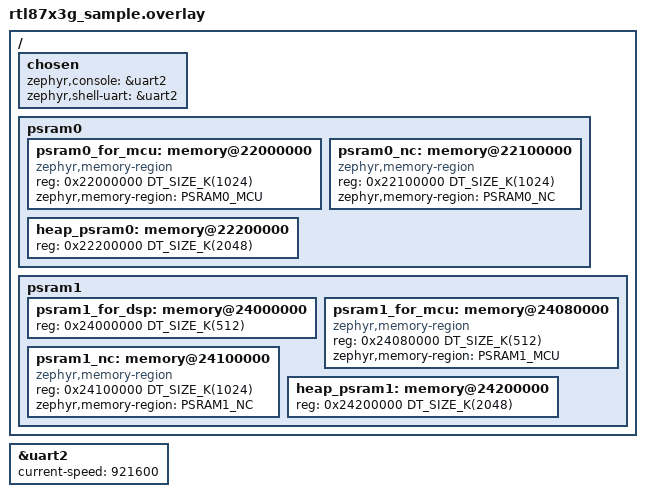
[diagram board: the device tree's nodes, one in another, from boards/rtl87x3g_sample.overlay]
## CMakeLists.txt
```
#
# Copyright (c) 2026, Realtek Semiconductor Corporation
#
# SPDX-License-Identifier: LicenseRef-Realtek-5-Clause
#

cmake_minimum_required(VERSION 3.20.0)

#===========version generation===========
include(${CMAKE_CURRENT_SOURCE_DIR}/../../cmake/version_generate.cmake)
generate_version()
#===========version generation===========
#===========post build===========
# post build should be called before find_package
include(${CMAKE_CURRENT_SOURCE_DIR}/../../cmake/post_build.cmake)
rtk_post_build()
#===========post build===========

find_package(Zephyr REQUIRED HINTS $ENV{ZEPHYR_BASE})
project(psram)

# app sources (recursive: src/ + src/platform/ + src/demo/)
FILE(GLOB_RECURSE app_sources src/*.c)
target_sources(app PRIVATE ${app_sources})
target_include_directories(app PRIVATE src src/platform src/demo)


zephyr_compile_options(
    -Wno-unused-variable
    -Wno-maybe-uninitialized
    -Wno-double-promotion
    -Wno-stringop-truncation
    -Wno-unused-function
    -Wno-missing-braces
    -Wno-use-after-free
    -Wno-parentheses
    -Wno-address
    -Wno-format-overflow
    -Wno-overflow
    -Wno-char-subscripts
    -Wno-enum-compare
)
```

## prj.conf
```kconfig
# MANDATORY for the psram heaps - do not remove.
#
# sys_heap stores each chunk's size/left-size in the chunk header, and the
# header width depends on the "Supported heap sizes" choice in
# zephyr/lib/heap/Kconfig:
#
#   SYS_HEAP_SMALL_ONLY : 16-bit fields -> a heap must be <= 262136 bytes
#   SYS_HEAP_BIG_ONLY   : 32-bit fields for every heap
#   SYS_HEAP_AUTO       : width picked per heap at runtime from its size
#
# That choice defaults to SYS_HEAP_SMALL_ONLY when CONFIG_SRAM_SIZE <= 256,
# and this SoC has 60 KB of SRAM, so the default applies here. The psram
# heaps (heap_psram0 / heap_psram1 in the board overlay) are 2 MB each, i.e.
# 262143 chunks, which does NOT fit in the 15-bit chunk size field.
#
# AUTO (rather than BIG_ONLY) keeps the 4-byte headers for the small sram /
# dtcm / itcm heaps and only pays the 8-byte headers on the psram heaps; the
# cost is a runtime branch on every header access plus a little code size.
CONFIG_SYS_HEAP_AUTO=y

CONFIG_LOG=y
CONFIG_CONSOLE=y
CONFIG_UART_CONSOLE=y
CONFIG_STDOUT_CONSOLE=y

CONFIG_SERIAL=y
CONFIG_SHELL=y
CONFIG_SHELL_BACKEND_SERIAL=y
CONFIG_PRINTK=y
CONFIG_SHELL_LOG_BACKEND=y
CONFIG_LOG_RTK=n

CONFIG_SHELL_STACK_SIZE=16384
CONFIG_SHELL_CMD_BUFF_SIZE=256
CONFIG_SHELL_ARGC_MAX=20
CONFIG_SHELL_BACKEND_SERIAL_TX_RING_BUFFER_SIZE=1024
CONFIG_SHELL_BACKEND_SERIAL_RX_RING_BUFFER_SIZE=256
CONFIG_SHELL_HISTORY=y
CONFIG_SHELL_HISTORY_BUFFER=512
CONFIG_SHELL_TAB=y
CONFIG_SHELL_TAB_AUTOCOMPLETION=y
```

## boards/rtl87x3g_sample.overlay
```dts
/*
 * Copyright (c) 2026, Realtek Semiconductor Corporation
 *
 * SPDX-License-Identifier: LicenseRef-Realtek-5-Clause
 */

/ {
    chosen {
        zephyr,console = &uart2;
        zephyr,shell-uart = &uart2;
    };
};

/* Zephyr shell / console UART (pins come from the board's uart2_default) */
&uart2 {
    status = "okay";
    current-speed = <921600>;
};

/ {
	/*
	 * Each psram chip's first 2 MB ("for_mcu") is split into a 1 MB
	 * cacheable region (*_MCU) and a 1 MB non-cacheable region (*_NC).
	 * Cacheability is set purely by the MPU attribute in app_mpu_config()
	 * (this SoC maps cacheable/non-cacheable to the SAME address), so these
	 * nodes only reserve the address ranges; the MPU regions are derived
	 * from these node addresses/sizes. The remaining 2 MB is the heap.
	 */
	psram0:psram0 {
		#address-cells = <1>;
		#size-cells = <1>;
		psram0_for_mcu: memory@22000000{
			compatible = "zephyr,memory-region";
			reg = <0x22000000 DT_SIZE_K(1024)>;
			zephyr,memory-region = "PSRAM0_MCU";
		};
		psram0_nc: memory@22100000{
			compatible = "zephyr,memory-region";
			reg = <0x22100000 DT_SIZE_K(1024)>;
			zephyr,memory-region = "PSRAM0_NC";
		};
        heap_psram0: memory@22200000{
            reg = <0x22200000 DT_SIZE_K(2048)>;
        };
	};

	psram1:psram1 {
		#address-cells = <1>;
		#size-cells = <1>;
		/* first 1 MB split: 512 KB cacheable MCU + 512 KB reserved for DSP.
		 * The DSP range may differ from applications and dsp firmwares.
		   Please check the psram1_for_dsp node before porting to an application. */
		psram1_for_dsp: memory@24000000{
			reg = <0x24000000 DT_SIZE_K(512)>;
		};
		psram1_for_mcu: memory@24080000{
			compatible = "zephyr,memory-region";
			reg = <0x24080000 DT_SIZE_K(512)>;
			zephyr,memory-region = "PSRAM1_MCU";
		};
		psram1_nc: memory@24100000{
			compatible = "zephyr,memory-region";
			reg = <0x24100000 DT_SIZE_K(1024)>;
			zephyr,memory-region = "PSRAM1_NC";
		};
        heap_psram1: memory@24200000{
            reg = <0x24200000 DT_SIZE_K(2048)>;
        };
	};

};
```

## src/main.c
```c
/*
 * Copyright (c) 2026, Realtek Semiconductor Corporation
 *
 * SPDX-License-Identifier: LicenseRef-Realtek-5-Clause
 */

/*
 * PSRAM usage sample. Demonstrates four ways to use the on-package psram:
 *   [1] static/global variables placed in a psram memory-region
 *   [2] psram as a heap (PSRAM0 + PSRAM1) via os_mem_alloc()
 *   [3] psram as a thread stack (dynamically created task, with a dynamic or a
 *       static psram stack)
 *   [4] cacheable psram access (cache/MPU set up in app_lower_init.c)
 *
 * All demos run once at boot and print a PASS/FAIL summary. When the shell is
 * enabled they can be re-run individually with e.g. `psram heap`, `psram all`.
 */

#include <stdio.h>
#include <zephyr/kernel.h>
#include <zephyr/shell/shell.h>

#include "app_lower_init.h"
#include "os_mem.h"
#include "osif_zephyr.h"
#include "psram_demo.h"

static int run_all(void)
{
    int fail = 0;

    fail += psram_static_var_demo();
    fail += psram_heap_demo();
    fail += psram_thread_stack_demo();
    fail += psram_cache_demo();

    printf("\n==== PSRAM sample summary: %s (%d demo group(s) failed) ====\n",
           fail ? "FAIL" : "ALL PASS", fail);
    return fail;
}

int main(void)
{
    printf("Hello World! %s\n", CONFIG_BOARD_TARGET);

    app_system_lower_init();
    psram_heap_init();

    run_all();

    return 0;
}

#ifdef CONFIG_SHELL
static int cmd_all(const struct shell *sh, size_t argc, char **argv)
{
    ARG_UNUSED(sh); ARG_UNUSED(argc); ARG_UNUSED(argv);
    run_all();
    return 0;
}

static int cmd_static(const struct shell *sh, size_t argc, char **argv)
{
    ARG_UNUSED(sh); ARG_UNUSED(argc); ARG_UNUSED(argv);
    psram_static_var_demo();
    return 0;
}

static int cmd_heap(const struct shell *sh, size_t argc, char **argv)
{
    ARG_UNUSED(sh); ARG_UNUSED(argc); ARG_UNUSED(argv);
    psram_heap_demo();
    return 0;
}

static int cmd_stack(const struct shell *sh, size_t argc, char **argv)
{
    ARG_UNUSED(sh); ARG_UNUSED(argc); ARG_UNUSED(argv);
    psram_thread_stack_demo();
    return 0;
}

static int cmd_cache(const struct shell *sh, size_t argc, char **argv)
{
    ARG_UNUSED(sh); ARG_UNUSED(argc); ARG_UNUSED(argv);
    psram_cache_demo();
    return 0;
}

static int cmd_peek(const struct shell *sh, size_t argc, char **argv)
{
    ARG_UNUSED(sh); ARG_UNUSED(argc); ARG_UNUSED(argv);
    psram_heap_peek();
    return 0;
}

SHELL_STATIC_SUBCMD_SET_CREATE(psram_cmds,
                               SHELL_CMD(all,    NULL, "run all psram demos",         cmd_all),
                               SHELL_CMD(static, NULL, "psram static-variable demo",  cmd_static),
                               SHELL_CMD(heap,   NULL, "psram heap demo",             cmd_heap),
                               SHELL_CMD(stack,  NULL, "psram thread-stack demo",     cmd_stack),
                               SHELL_CMD(cache,  NULL, "psram cache demo",            cmd_cache),
                               SHELL_CMD(peek,   NULL, "psram heap usage peek",       cmd_peek),
                               SHELL_SUBCMD_SET_END
                              );
SHELL_CMD_REGISTER(psram, &psram_cmds, "PSRAM usage demos", NULL);
#endif /* CONFIG_SHELL */
```
